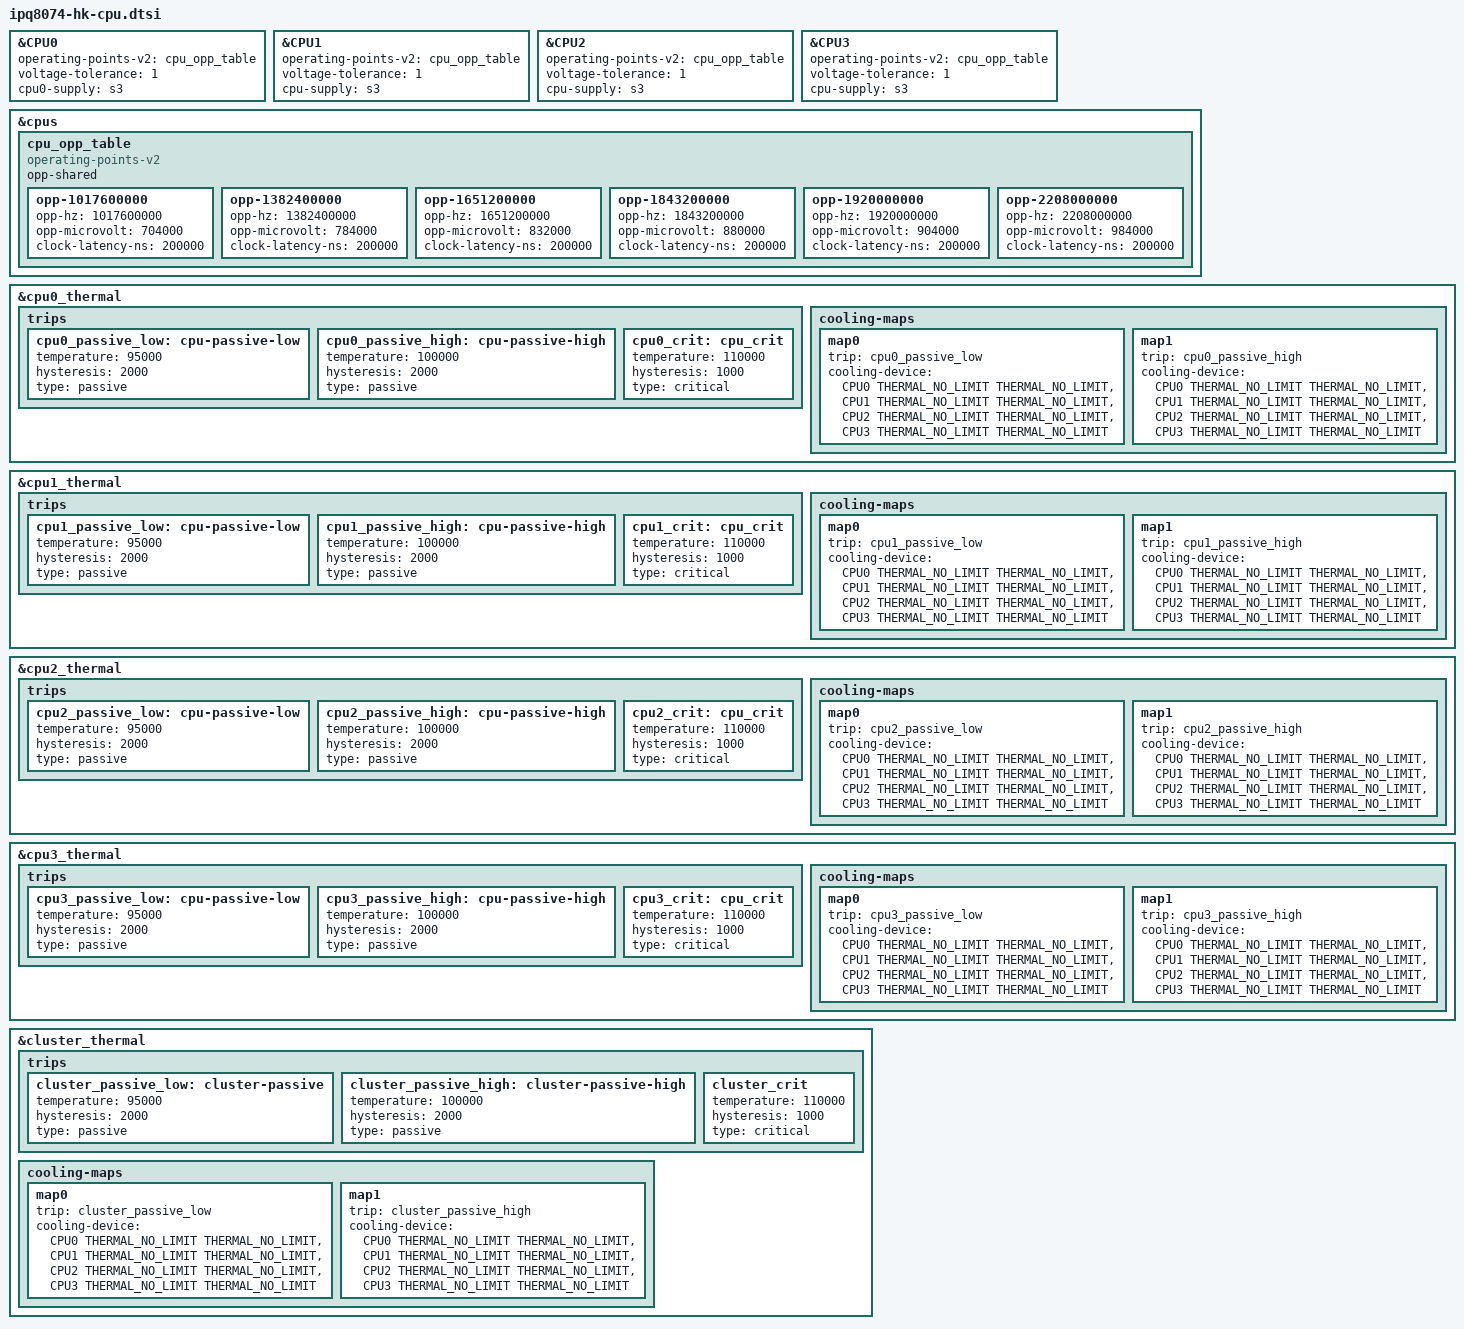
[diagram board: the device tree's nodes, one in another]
// SPDX-License-Identifier: GPL-2.0-only

&CPU0 {
	operating-points-v2 = <&cpu_opp_table>;
	voltage-tolerance = <1>;
	cpu0-supply = <&s3>;
};

&CPU1 {
	operating-points-v2 = <&cpu_opp_table>;
	voltage-tolerance = <1>;
	cpu-supply = <&s3>;
};

&CPU2 {
	operating-points-v2 = <&cpu_opp_table>;
	voltage-tolerance = <1>;
	cpu-supply = <&s3>;
};

&CPU3 {
	operating-points-v2 = <&cpu_opp_table>;
	voltage-tolerance = <1>;
	cpu-supply = <&s3>;
};

&cpus {
	cpu_opp_table: cpu_opp_table {
		compatible = "operating-points-v2";
		opp-shared;

		opp-1017600000 {
			opp-hz = /bits/ 64 <1017600000>;
			opp-microvolt = <704000>;
			clock-latency-ns = <200000>;
		};
		opp-1382400000 {
			opp-hz = /bits/ 64 <1382400000>;
			opp-microvolt = <784000>;
			clock-latency-ns = <200000>;
		};
		opp-1651200000 {
			opp-hz = /bits/ 64 <1651200000>;
			opp-microvolt = <832000>;
			clock-latency-ns = <200000>;
		};
		opp-1843200000 {
			opp-hz = /bits/ 64 <1843200000>;
			opp-microvolt = <880000>;
			clock-latency-ns = <200000>;
		};
		opp-1920000000 {
			opp-hz = /bits/ 64 <1920000000>;
			opp-microvolt = <904000>;
			clock-latency-ns = <200000>;
		};
		opp-2208000000 {
			opp-hz = /bits/ 64 <2208000000>;
			opp-microvolt = <984000>;
			clock-latency-ns = <200000>;
		};
	};
};

&cpu0_thermal {
	trips {
		cpu0_passive_low: cpu-passive-low {
			temperature = <95000>;
			hysteresis = <2000>;
			type = "passive";
		};

		cpu0_passive_high: cpu-passive-high {
			temperature = <100000>;
			hysteresis = <2000>;
			type = "passive";
		};

		cpu0_crit: cpu_crit {
			temperature = <110000>;
			hysteresis = <1000>;
			type = "critical";
		};
	};

	cooling-maps {
		map0 {
			trip = <&cpu0_passive_low>;
			cooling-device = <&CPU0 THERMAL_NO_LIMIT THERMAL_NO_LIMIT>,
					 <&CPU1 THERMAL_NO_LIMIT THERMAL_NO_LIMIT>,
					 <&CPU2 THERMAL_NO_LIMIT THERMAL_NO_LIMIT>,
					 <&CPU3 THERMAL_NO_LIMIT THERMAL_NO_LIMIT>;
		};
		map1 {
			trip = <&cpu0_passive_high>;
			cooling-device = <&CPU0 THERMAL_NO_LIMIT THERMAL_NO_LIMIT>,
					 <&CPU1 THERMAL_NO_LIMIT THERMAL_NO_LIMIT>,
					 <&CPU2 THERMAL_NO_LIMIT THERMAL_NO_LIMIT>,
					 <&CPU3 THERMAL_NO_LIMIT THERMAL_NO_LIMIT>;
		};
	};
};

&cpu1_thermal {
	trips {
		cpu1_passive_low: cpu-passive-low {
			temperature = <95000>;
			hysteresis = <2000>;
			type = "passive";
		};

		cpu1_passive_high: cpu-passive-high {
			temperature = <100000>;
			hysteresis = <2000>;
			type = "passive";
		};

		cpu1_crit: cpu_crit {
			temperature = <110000>;
			hysteresis = <1000>;
			type = "critical";
		};
	};

	cooling-maps {
		map0 {
			trip = <&cpu1_passive_low>;
			cooling-device = <&CPU0 THERMAL_NO_LIMIT THERMAL_NO_LIMIT>,
					 <&CPU1 THERMAL_NO_LIMIT THERMAL_NO_LIMIT>,
					 <&CPU2 THERMAL_NO_LIMIT THERMAL_NO_LIMIT>,
					 <&CPU3 THERMAL_NO_LIMIT THERMAL_NO_LIMIT>;
		};
		map1 {
			trip = <&cpu1_passive_high>;
			cooling-device = <&CPU0 THERMAL_NO_LIMIT THERMAL_NO_LIMIT>,
					 <&CPU1 THERMAL_NO_LIMIT THERMAL_NO_LIMIT>,
					 <&CPU2 THERMAL_NO_LIMIT THERMAL_NO_LIMIT>,
					 <&CPU3 THERMAL_NO_LIMIT THERMAL_NO_LIMIT>;
		};
	};
};

&cpu2_thermal {
	trips {
		cpu2_passive_low: cpu-passive-low {
			temperature = <95000>;
			hysteresis = <2000>;
			type = "passive";
		};

		cpu2_passive_high: cpu-passive-high {
			temperature = <100000>;
			hysteresis = <2000>;
			type = "passive";
		};

		cpu2_crit: cpu_crit {
			temperature = <110000>;
			hysteresis = <1000>;
			type = "critical";
		};
	};

	cooling-maps {
		map0 {
			trip = <&cpu2_passive_low>;
			cooling-device = <&CPU0 THERMAL_NO_LIMIT THERMAL_NO_LIMIT>,
					 <&CPU1 THERMAL_NO_LIMIT THERMAL_NO_LIMIT>,
					 <&CPU2 THERMAL_NO_LIMIT THERMAL_NO_LIMIT>,
					 <&CPU3 THERMAL_NO_LIMIT THERMAL_NO_LIMIT>;
		};
		map1 {
			trip = <&cpu2_passive_high>;
			cooling-device = <&CPU0 THERMAL_NO_LIMIT THERMAL_NO_LIMIT>,
					 <&CPU1 THERMAL_NO_LIMIT THERMAL_NO_LIMIT>,
					 <&CPU2 THERMAL_NO_LIMIT THERMAL_NO_LIMIT>,
					 <&CPU3 THERMAL_NO_LIMIT THERMAL_NO_LIMIT>;
		};
	};
};

&cpu3_thermal {
	trips {
		cpu3_passive_low: cpu-passive-low {
			temperature = <95000>;
			hysteresis = <2000>;
			type = "passive";
		};

		cpu3_passive_high: cpu-passive-high {
			temperature = <100000>;
			hysteresis = <2000>;
			type = "passive";
		};

		cpu3_crit: cpu_crit {
			temperature = <110000>;
			hysteresis = <1000>;
			type = "critical";
		};
	};

	cooling-maps {
		map0 {
			trip = <&cpu3_passive_low>;
			cooling-device = <&CPU0 THERMAL_NO_LIMIT THERMAL_NO_LIMIT>,
					 <&CPU1 THERMAL_NO_LIMIT THERMAL_NO_LIMIT>,
					 <&CPU2 THERMAL_NO_LIMIT THERMAL_NO_LIMIT>,
					 <&CPU3 THERMAL_NO_LIMIT THERMAL_NO_LIMIT>;
		};
		map1 {
			trip = <&cpu3_passive_high>;
			cooling-device = <&CPU0 THERMAL_NO_LIMIT THERMAL_NO_LIMIT>,
					 <&CPU1 THERMAL_NO_LIMIT THERMAL_NO_LIMIT>,
					 <&CPU2 THERMAL_NO_LIMIT THERMAL_NO_LIMIT>,
					 <&CPU3 THERMAL_NO_LIMIT THERMAL_NO_LIMIT>;
		};
	};
};

&cluster_thermal {
	trips {
		cluster_passive_low: cluster-passive {
			temperature = <95000>;
			hysteresis = <2000>;
			type = "passive";
		};

		cluster_passive_high: cluster-passive-high {
			temperature = <100000>;
			hysteresis = <2000>;
			type = "passive";
		};

		cluster_crit: cluster_crit {
			temperature = <110000>;
			hysteresis = <1000>;
			type = "critical";
		};
	};

	cooling-maps {
		map0 {
			trip = <&cluster_passive_low>;
			cooling-device = <&CPU0 THERMAL_NO_LIMIT THERMAL_NO_LIMIT>,
					 <&CPU1 THERMAL_NO_LIMIT THERMAL_NO_LIMIT>,
					 <&CPU2 THERMAL_NO_LIMIT THERMAL_NO_LIMIT>,
					 <&CPU3 THERMAL_NO_LIMIT THERMAL_NO_LIMIT>;
		};
		map1 {
			trip = <&cluster_passive_high>;
			cooling-device = <&CPU0 THERMAL_NO_LIMIT THERMAL_NO_LIMIT>,
					 <&CPU1 THERMAL_NO_LIMIT THERMAL_NO_LIMIT>,
					 <&CPU2 THERMAL_NO_LIMIT THERMAL_NO_LIMIT>,
					 <&CPU3 THERMAL_NO_LIMIT THERMAL_NO_LIMIT>;
		};
	};
};
